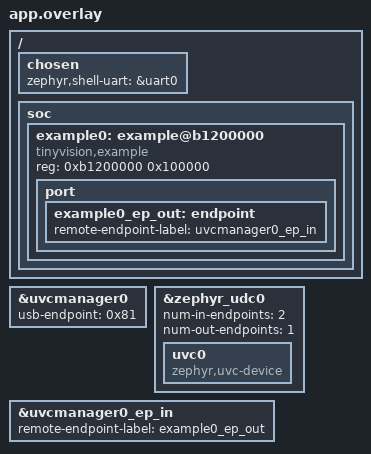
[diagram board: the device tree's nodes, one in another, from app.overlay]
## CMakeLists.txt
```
# Copyright (c) 2024 tinyVision.ai Inc.
# SPDX-License-Identifier: Apache-2.0

cmake_minimum_required(VERSION 3.20.0)
find_package(Zephyr REQUIRED HINTS $ENV{ZEPHYR_BASE})
project(app)

target_sources(app PRIVATE src/usb.c)
target_sources(app PRIVATE src/main.c)

# Run some code from RAM for performance during enumeration
zephyr_code_relocate(LIBRARY drivers__usb__udc LOCATION RAM)
zephyr_code_relocate(LIBRARY drivers__usbd LOCATION RAM)
```

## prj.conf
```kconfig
CONFIG_MINIMAL_LIBC=y
CONFIG_ASSERT=y
CONFIG_SERIAL=y

# SHELL
CONFIG_SHELL=y
CONFIG_I2C_SHELL=y
CONFIG_VIDEO_SHELL=y
CONFIG_KERNEL_SHELL=y
CONFIG_SHELL_BACKEND_SERIAL_API_INTERRUPT_DRIVEN=y
CONFIG_SHELL_BACKEND_SERIAL_TX_RING_BUFFER_SIZE=64

# USB
CONFIG_UDC_DRIVER=y
CONFIG_USB_DEVICE_STACK_NEXT=y
CONFIG_USBD_VIDEO_CLASS=y

# VIDEO
CONFIG_VIDEO=y
CONFIG_VIDEO_BUFFER_POOL_SZ_MAX=4096
CONFIG_VIDEO_BUFFER_POOL_NUM_MAX=1

# LOG
CONFIG_LOG=y
CONFIG_LOG_MODE_MINIMAL=y
CONFIG_UDC_DRIVER_LOG_LEVEL_INF=y
CONFIG_USBD_LOG_LEVEL_INF=y
CONFIG_USBD_VIDEO_LOG_LEVEL_INF=y
CONFIG_VIDEO_LOG_LEVEL_DBG=y

CONFIG_EVENT_LOGGER=y

CONFIG_I2C_OPENCORES_ALT=y
```

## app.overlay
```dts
/*
 * Copyright (c) 2024-2025 tinyVision.ai Inc.
 *
 * SPDX-License-Identifier: Apache-2.0
 */

#include <riscv/tinyvision/add_uvcmanager0.dtsi>

#include <riscv/tinyvision/add_i2c0_pll.dtsi>

/ {
	chosen {
		zephyr,shell-uart = &uart0;
	};
};

/* USB interfaces */

&uvcmanager0 {
	usb-endpoint = <0x81>;
};

&zephyr_udc0 {
	num-in-endpoints = <2>;
	num-out-endpoints = <1>;
	status = "okay";

	uvc0: uvc0 {
		compatible = "zephyr,uvc-device";
	};
};

&uvcmanager0 {
	usb-endpoint = <0x81>;
};

/* Camera 0 config */

&uvcmanager0_ep_in {
	remote-endpoint-label = "example0_ep_out";
};

/ {
	soc {
		example0: example@b1200000 {
			compatible = "tinyvision,example";
			reg = <0xb1200000 0x100000>;

			port {
				example0_ep_out: endpoint {
					remote-endpoint-label = "uvcmanager0_ep_in";
				};
			};
		};
	};
};
```

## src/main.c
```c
#include <zephyr/drivers/video.h>
#include <zephyr/drivers/video-controls.h>
#include <zephyr/usb/class/usbd_uvc.h>
#include <zephyr/logging/log.h>

LOG_MODULE_REGISTER(app_main, LOG_LEVEL_INF);

static const struct device *const uvc0_dev = DEVICE_DT_GET(DT_NODELABEL(uvc0));
static const struct device *const uvcmanager0_dev = DEVICE_DT_GET(DT_NODELABEL(uvcmanager0));

int app_usb_init(void);

int main(void)
{
	int ret;

	uvc_set_video_dev(uvc0_dev, uvcmanager0_dev);

	LOG_INF("Initializing USB and associated USB classes");

	ret = app_usb_init();
	if (ret != 0) {
		LOG_ERR("Failed to initialize USB");
		return ret;
	}

	LOG_INF("Done, exiting main() and letting the USB stack run");

	return 0;
}
```
